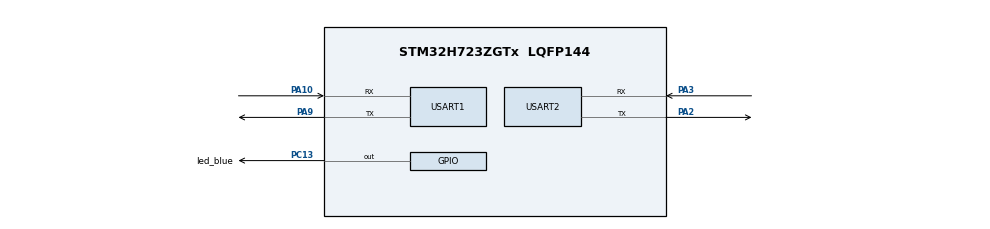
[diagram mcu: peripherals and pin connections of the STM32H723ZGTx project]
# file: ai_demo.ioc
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Mcu.Family=STM32H7
Mcu.Name=STM32H723ZGTx
Mcu.Package=LQFP144
NVIC.PriorityGroup=NVIC_PRIORITYGROUP_4
NVIC.TIM6_DAC_IRQn=true\:1\:0\:true\:false\:true\:true\:true\:true
NVIC.USART1_IRQn=true\:0\:0\:false\:false\:true\:true\:true\:true
NVIC.USART2_IRQn=true\:2\:0\:true\:false\:true\:true\:true\:true
PA10.Mode=Asynchronous
PA10.Signal=USART1_RX
PA2.GPIO_Speed=GPIO_SPEED_FREQ_HIGH
PA2.Mode=Asynchronous
PA2.Signal=USART2_TX
PA3.GPIO_Speed=GPIO_SPEED_FREQ_HIGH
PA3.Mode=Asynchronous
PA3.Signal=USART2_RX
PA9.Mode=Asynchronous
PA9.Signal=USART1_TX
PC13.GPIO_Label=led_blue
PC13.Signal=GPIO_Output
PC14-OSC32_IN.Mode=LSE-External-Oscillator
PC14-OSC32_IN.Signal=RCC_OSC32_IN
PC15-OSC32_OUT.Mode=LSE-External-Oscillator
PC15-OSC32_OUT.Signal=RCC_OSC32_OUT
PH0-OSC_IN.Mode=HSE-External-Oscillator
PH0-OSC_IN.Signal=RCC_OSC_IN
PH1-OSC_OUT.Mode=HSE-External-Oscillator
PH1-OSC_OUT.Signal=RCC_OSC_OUT
ProjectManager.HeapSize=0x200
ProjectManager.StackSize=0x400
ProjectManager.TargetToolchain=STM32CubeIDE
RCC.ADCFreq_Value=129000000
RCC.APB1Freq_Value=137500000
RCC.APB2Freq_Value=137500000
RCC.APB3Freq_Value=137500000
RCC.APB4Freq_Value=137500000
RCC.CortexFreq_Value=550000000
RCC.D1PPRE=RCC_APB3_DIV2
RCC.D2PPRE1=RCC_APB1_DIV2
RCC.D2PPRE2=RCC_APB2_DIV2
RCC.D3PPRE=RCC_APB4_DIV2
RCC.DIVM1=4
RCC.DIVN1=34
RCC.DIVP1=1
RCC.HCLKFreq_Value=275000000
RCC.HPRE=RCC_HCLK_DIV2
RCC.PLL2FRACN=0
RCC.PLL3FRACN=0
RCC.PLLFRACN=3072
RCC.SYSCLKFreq_VALUE=550000000
RCC.SYSCLKSource=RCC_SYSCLKSOURCE_PLLCLK
RCC.USBFreq_Value=275000000
TIM6.AutoReloadPreload=TIM_AUTORELOAD_PRELOAD_ENABLE
TIM6.Period=1000 - 1
TIM6.Prescaler=275 - 1
USART1.VirtualMode-Asynchronous=VM_ASYNC
USART2.VirtualMode-Asynchronous=VM_ASYNC
VP_CRC_VS_CRC.Mode=CRC_Activate
VP_DTS_VS-DTS.Mode=DTS
VP_TIM6_VS_ClockSourceINT.Mode=Enable_Timer
board=custom

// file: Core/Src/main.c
/* USER CODE BEGIN Header */
/**
  ******************************************************************************
  * @file           : main.c
  * @brief          : Main program body
  ******************************************************************************
  * @attention
  *
  * Copyright (c) 2023 STMicroelectronics.
  * All rights reserved.
  *
  * This software is licensed under terms that can be found in the LICENSE file
  * in the root directory of this software component.
  * If no LICENSE file comes with this software, it is provided AS-IS.
  *
  ******************************************************************************
  */
/* USER CODE END Header */
#include "main.h"
#include "crc.h"
#include "dts.h"
#include "tim.h"
#include "usart.h"
#include "gpio.h"

/* USER CODE BEGIN Includes */
#include "headfiles.h"
/* USER CODE END Includes */

void SystemClock_Config(void);

int main(void) {

    /* MCU Configuration--------------------------------------------------------*/

    /* Reset of all peripherals, Initializes the Flash interface and the Systick. */
    HAL_Init();

    /* Configure the system clock */
    SystemClock_Config();

    /* Initialize all configured peripherals */
    MX_GPIO_Init();
    MX_DTS_Init();
    MX_TIM6_Init();
    MX_USART1_UART_Init();
    MX_CRC_Init();
    MX_USART2_UART_Init();
    /* USER CODE BEGIN 2 */
    all_init();
    /* USER CODE END 2 */

    /* Infinite loop */
    while (1) {

    }
}

void SystemClock_Config(void) {
    RCC_OscInitTypeDef RCC_OscInitStruct = {0};
    RCC_ClkInitTypeDef RCC_ClkInitStruct = {0};

    /** Supply configuration update enable
    */
    HAL_PWREx_ConfigSupply(PWR_LDO_SUPPLY);

    /** Configure the main internal regulator output voltage
    */
    __HAL_PWR_VOLTAGESCALING_CONFIG(PWR_REGULATOR_VOLTAGE_SCALE0);

    while (!__HAL_PWR_GET_FLAG(PWR_FLAG_VOSRDY)) {}

    /** Initializes the RCC Oscillators according to the specified parameters
    * in the RCC_OscInitTypeDef structure.
    */
    RCC_OscInitStruct.OscillatorType = RCC_OSCILLATORTYPE_HSI;
    RCC_OscInitStruct.HSIState = RCC_HSI_DIV1;
    RCC_OscInitStruct.HSICalibrationValue = 64;
    RCC_OscInitStruct.PLL.PLLState = RCC_PLL_ON;
    RCC_OscInitStruct.PLL.PLLSource = RCC_PLLSOURCE_HSI;
    RCC_OscInitStruct.PLL.PLLM = 4;
    RCC_OscInitStruct.PLL.PLLN = 34;
    RCC_OscInitStruct.PLL.PLLP = 1;
    RCC_OscInitStruct.PLL.PLLQ = 2;
    RCC_OscInitStruct.PLL.PLLR = 2;
    RCC_OscInitStruct.PLL.PLLRGE = RCC_PLL1VCIRANGE_3;
    RCC_OscInitStruct.PLL.PLLVCOSEL = RCC_PLL1VCOWIDE;
    RCC_OscInitStruct.PLL.PLLFRACN = 3072;
    if (HAL_RCC_OscConfig(&RCC_OscInitStruct) != HAL_OK) {
        Error_Handler();
    }

    /** Initializes the CPU, AHB and APB buses clocks
    */
    RCC_ClkInitStruct.ClockType = RCC_CLOCKTYPE_HCLK | RCC_CLOCKTYPE_SYSCLK
                                  | RCC_CLOCKTYPE_PCLK1 | RCC_CLOCKTYPE_PCLK2
                                  | RCC_CLOCKTYPE_D3PCLK1 | RCC_CLOCKTYPE_D1PCLK1;
    RCC_ClkInitStruct.SYSCLKSource = RCC_SYSCLKSOURCE_PLLCLK;
    RCC_ClkInitStruct.SYSCLKDivider = RCC_SYSCLK_DIV1;
    RCC_ClkInitStruct.AHBCLKDivider = RCC_HCLK_DIV2;
    RCC_ClkInitStruct.APB3CLKDivider = RCC_APB3_DIV2;
    RCC_ClkInitStruct.APB1CLKDivider = RCC_APB1_DIV2;
    RCC_ClkInitStruct.APB2CLKDivider = RCC_APB2_DIV2;
    RCC_ClkInitStruct.APB4CLKDivider = RCC_APB4_DIV2;

    if (HAL_RCC_ClockConfig(&RCC_ClkInitStruct, FLASH_LATENCY_3) != HAL_OK) {
        Error_Handler();
    }
}

void Error_Handler(void) {
    __disable_irq();
    while (1) {
    }
}
